# hsm_secure register map
Vendor: Texas Instruments
Peripheral module from a debugger description file (folder CC35X1).
Registers are 32-bit, read-only, reset 0x0 unless marked. A register's access mark holds for its fields unless they carry their own. Offsets are as the file gives them; lines under a group give offsets from that group; [hi:lo] are bit positions; {n}, {i} and the like mark numbered series; 'fields as' and 'values as' point back to an identical list; <NAME> marks a mode.

## hsm_secure
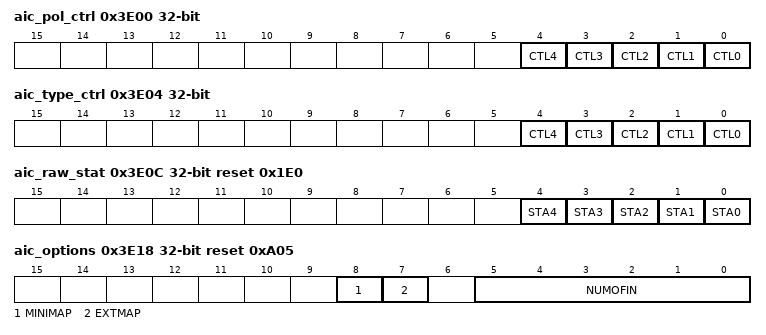
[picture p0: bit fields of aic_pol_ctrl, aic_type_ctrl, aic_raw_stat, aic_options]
0x3E00 aic_pol_ctrl access per field — AIC Polarity Control Register
  [n] CTL{n} rw (n=0..4) — Individual polarity (high level/rising edge or low level/falling edge) control bits per interrupt input: 0b = Low level/falling edge 1b = High level/rising edge.
0x3E04 aic_type_ctrl access per field — AIC Type Control Register
  [n] CTL{n} rw (n=0..4) — Signal type (level or edge) control bits for each interrupt input: 0b = level (the interrupt source level determines the raw status). 1b = edge (the interrupt source is connected to an edge detector and the edge detector output determines the raw status).
0x3E08 aic_enable_ctrl access per field — AIC Enable Control Register
  [4:0] CTL rw — Individual enable control bits per interrupt input: 0b = Disabled. 1b = Enabled
0x3E0C aic_raw_stat reset 0x1E0 (reset mask 0xFFFFFFE0) — AIC Raw Source Status Register
  [n] STA{n} (n=0..4) — Individual interrupt status bit before masking with enable_ctrl_r[{n}] (programmable, reset to 'low level' mode): 0b = Inactive, 1b = Pending.
0x3E10 aic_enabled_stat — AIC Enabled Status Register
  [4:0] STA — These bits reflect the status of the interrupts after polarity control and optional edge detection, gated with bits in AIC_ENABLE_CTRL register: 0b = Inactive. 1b = Pending.
0x3E14 aic_enable_clr wo — AIC Enable Clear Register
  [4:0] CLR — Individual interrupt disable bits per interrupt input: 0b = No effect. 1b = Clear the corresponding bit in the AIC_ENABLE_CTRL register, disabling the interrupt. After writing a 1b, there is no need to write a 0b.
0x3E18 aic_options reset 0xA05 (reset mask 0xFFFFFE3F)
  [8] MINIMAP — Mini register map.
  [7] EXTMAP — Extended register map.
  [5:0] NUMOFIN — The number of interrupt request inputs.
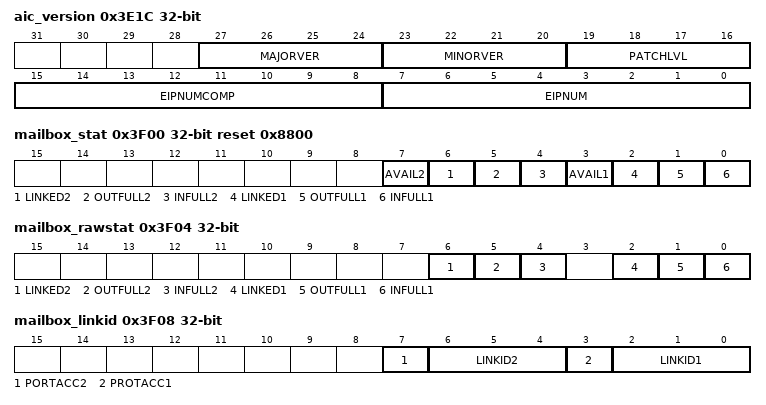
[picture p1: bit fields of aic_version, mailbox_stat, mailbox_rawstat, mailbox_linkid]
0x3E1C aic_version reset not defined
  [27:24] MAJORVER — These bits encode the major version number for the EIP-201 module.
  [23:20] MINORVER — These bits encode the minor version number for the EIP-201 module.
  [19:16] PATCHLVL — These bits encode the hardware patch level for the EIP-201 module, starting at value 0 on the first release.
  [15:8] EIPNUMCOMP — These bits simply contain the complement of bits [7:0], used by a driver to ascertain that this version register is indeed read.
  [7:0] EIPNUM — These bits encode the Rambus EIP number.
0x3F00 mailbox_stat reset 0x8800 (reset mask 0xFFFFFF00) — Mailbox Status Register
  [7] AVAIL2 — (set)-Input Mailbox is linked to a Host or is filled, (Clear)- Input Mailbox is available for linking by this Host
  [6] LINKED2 — (set)-This Host is linked to Mailbox, (Clear)-This Host is not linked to Mailbox
  [5] OUTFULL2 — (set)-Output Mailbox contains an output token, (Clear)-Output Mailbox is empty
  [4] INFULL2 — (set)-Input Mailbox contains a token that is handed over to Internal Controller, (Clear)-Input Mailbox is ready to rceive new token
  [3] AVAIL1 — (set)-Input Mailbox is linked to a Host or is filled, (Clear)- Input Mailbox is available for linking by this Host
  [2] LINKED1 — (set)-This Host is linked to Mailbox, (Clear)-This Host is not linked to Mailbox
  [1] OUTFULL1 — (set)-Output Mailbox contains an output token, (Clear)-Output Mailbox is empty
  [0] INFULL1 — (set)-Input Mailbox contains a token that is handed over to Internal Controller, (Clear)-Input Mailbox is ready to rceive new token
0x3F04 mailbox_rawstat — Raw (unmasked) Mailbox Status Register
  [6] LINKED2 — (set)-This Host is linked to Mailbox mbx%d , (Clear)-This Host is not linked to Mailbox mbx%d
  [5] OUTFULL2 — (set)-Output Mailbox contains an output token, (Clear)-Output Mailbox mbx%d is empty
  [4] INFULL2 — (set)-Input Mailbox contains a token that is handed over to Internal Controller, (Clear)-Input Mailbox mbx%d is ready to rceive new token
  [2] LINKED1 — (set)-This Host is linked to Mailbox mbx%d , (Clear)-This Host is not linked to Mailbox mbx%d
  [1] OUTFULL1 — (set)-Output Mailbox contains an output token, (Clear)-Output Mailbox mbx%d is empty
  [0] INFULL1 — (set)-Input Mailbox contains a token that is handed over to Internal Controller, (Clear)-Input Mailbox mbx%d is ready to rceive new token
0x3F08 mailbox_linkid — Mailbox Status - linked Host IDs Register
  [7] PORTACC2 — 0: Mailbox 2 can be accessed by the Host using protected or non-protected access. 1: Mailbox 2 is only accessible if the Host uses protected access.
  [6:4] LINKID2 — Bits[1:0]Host cpu_id of the Host linked to the Mailbox, bit[2] Set - Mailbox is only accessible if Host uses protected access, Clear - Mailbox accessed with protected of non-protected access
  [3] PROTACC1 — 0: Mailbox 1 can be accessed by the Host using protected or non-protected access. 1: Mailbox 1 is only accessible if the Host uses protected access.
  [2:0] LINKID1 — Bits[1:0]Host cpu_id of the Host linked to the Mailbox, bit[2] Set - Mailbox is only accessible if Host uses protected access, Clear - Mailbox accessed with protected of non-protected access
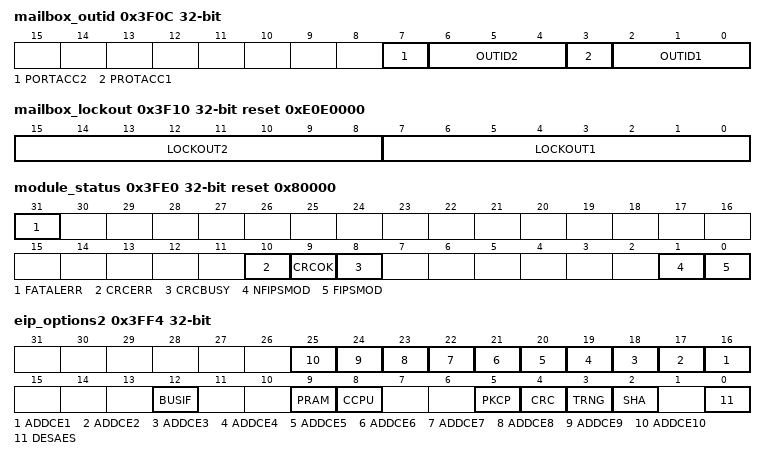
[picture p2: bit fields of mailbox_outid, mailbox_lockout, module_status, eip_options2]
0x3F0C mailbox_outid — Mailbox Status - output Host IDs Register
  [7] PORTACC2 — 0: Output mailbox 2 can be accessed by the Host using protected or non-protected access. 1: Output mailbox 2 is only accessible if the Host uses protected access.
  [6:4] OUTID2 — Bit[1,0] Host cpu_id of the Host allowed to read a result from the Mailbox, bit[2] Set - Out Mailbox is only accessible if Host uses protected access, Clear - Output Mailbox accessed with protected of non-protected access
  [3] PROTACC1 — 0: Output mailbox 1 can be accessed by the Host using protected or non-protected access. 1: Output mailbox 1 is only accessible if the Host uses protected access.
  [2:0] OUTID1 — Bit[1,0] Host cpu_id of the Host allowed to read a result from the Mailbox, bit[2] Set - Out Mailbox is only accessible if Host uses protected access, Clear - Output Mailbox accessed with protected of non-protected access
0x3F10 mailbox_lockout access per field reset 0xE0E0000 (reset mask 0xFFFF0000) — Host/Mailbox1-4 lockout control Register
  [15:8] LOCKOUT2 rw — Bit map indicates which Hosts are blocked from accessing mailbox
  [7:0] LOCKOUT1 rw — Bit map indicates which Hosts are blocked from accessing mailbox
0x3FE0 module_status reset 0x80000 (reset mask 0x7FFFF800)
  [31] FATALERR — Read-Only. Set if fatal error occured
  [10] CRCERR — Read-Only. Set if CRC on ProgramROM is fails
  [9] CRCOK — Read-Only. Set if CRC on ProgramROM is passes
  [8] CRCBUSY — Read-Only. Set if CRC on ProgramROM is busy
  [1] NFIPSMOD — Read-Only. Set if VaultIP is in non-FIPS mode
  [0] FIPSMOD — Read-Only. Set if VaultIP is in FIPS mode
0x3FF4 eip_options2 reset not defined — VaultIP configured options(2)
  [n+15] ADDCE{n} (n=1..10) — Set - an additional crypto engine is available in hardware as custom engine{n}
  [12] BUSIF — Bus interface type, for both Master and Slave: 0b = 32-bit AHB, 1b = 32-bit AXI
  [9] PRAM — 1b = downloadable RAM based firmware program memory. 0b = ROM only firmware program memory.
  [8] CCPU — C capable local cpu available
  [5] PKCP — PKCP Engine available
  [4] CRC — CRC calculation available
  [3] TRNG — Set - TRNG engine available
  [2] SHA — Set - SHA1/SHA2 combination core available
  [0] DESAES — Set - (3)DES/AES combination crypto core available
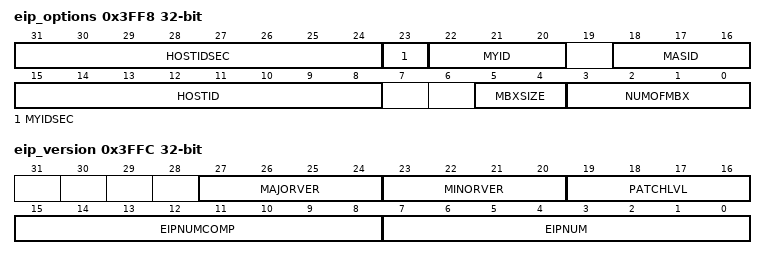
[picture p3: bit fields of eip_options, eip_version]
0x3FF8 eip_options reset not defined — VaultIP configured options(1)
  [31:24] HOSTIDSEC — Bits to indicate which of the 8 possible cpu_id codes on the bus interface are active Hosts with secure access
  [23] MYIDSEC — Indicates the current protection bit values of the Host actually reading the register
  [22:20] MYID — Slave & Master interface support protection bit (secure/non-secure) accesses
  [18:16] MASID — Value of the cpu_id that designates the Master Host
  [15:8] HOSTID — Bits to indicate which of the 8 possible cpu_id codes on the bus interface are active
  [5:4] MBXSIZE — Implemented size of Mailbox pairs - 00b-128bytes, 01b-256bytes, 10b-512bytes, 11b-1Kbyte
  [3:0] NUMOFMBX — Number of Input/Output Mailbox pairs
0x3FFC eip_version reset not defined — Standard EIP version register
  [27:24] MAJORVER — Major Version release number for this module
  [23:20] MINORVER — Minor Version release number for this module
  [19:16] PATCHLVL — Hardware Patch Level for this module
  [15:8] EIPNUMCOMP — Bit by Bit compliment of EIP Number
  [7:0] EIPNUM — RAMBUS EIP number - EIP130
